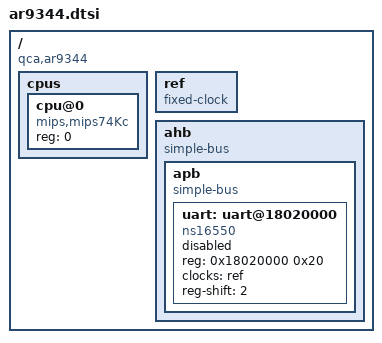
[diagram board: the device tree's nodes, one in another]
#include <dt-bindings/clock/ath79-clk.h>

/ {
	compatible = "qca,ar9344";

	#address-cells = <1>;
	#size-cells = <1>;

	cpus {
		#address-cells = <1>;
		#size-cells = <0>;

		cpu@0 {
			device_type = "cpu";
			compatible = "mips,mips74Kc";
		//	clocks = <&pll ATH79_CLK_CPU>;
			reg = <0>;
		};
	};

	ref: ref {
		compatible = "fixed-clock";
		#clock-cells = <0>;
	};

	ahb {
		compatible = "simple-bus";
		ranges;

		#address-cells = <1>;
		#size-cells = <1>;

	//	interrupt-parent = <&cpuintc>;

		apb {
			compatible = "simple-bus";
			ranges;

			#address-cells = <1>;
			#size-cells = <1>;

			uart: uart@18020000 {
				compatible = "ns16550";
				reg = <0x18020000 0x20>;

				clocks = <&ref>;
				clock-names = "uart";
				reg-shift = <2>;

				status = "disabled";
			};

/*
			pll: pll-controller@18050000 {
				compatible = "qca,ar9344-pll";
				reg = <0x18050000 0x100>;

				clocks = <&ref>;
				clock-names = "ref";

				#clock-cells = <1>;
			};
*/
		};

	};

};
